# liliumFP1_application register map
Vendor: Nordic Semiconductor; Series: liliumFP1; File version: 1
CPU: CM33 r0p4, little endian, MPU, FPU, 3 interrupt priority bits, 480 interrupts
Registers are 32-bit, read-write, reset 0x0 unless marked. A register's access mark holds for its fields unless they carry their own. Offsets are from the block's base; [hi:lo] are bit positions; {n}, {i} and the like mark numbered series; 'fields as' and 'values as' point back to an identical list.

## BELLBOARD_NS — BELLBOARD APB registers 0
Base 0x4F09A000
Same registers: BELLBOARD_S 0x5F09A000
{0x0+4i} TASKS_TRIGGER[{i}] (i=0..31) wo — Description collection: Task TRIGGER[n]
  [0] TASKS_TRIGGER — Task TRIGGER[n]
    1=Trigger task
{0x100+4i} EVENTS_TRIGGERED[{i}] (i=0..31) — Description collection: Event TRIGGERED[n]
  [0] EVENTS_TRIGGERED — Event TRIGGERED[n]
    0=NotGenerated (Event not generated); 1=Generated (Event generated)
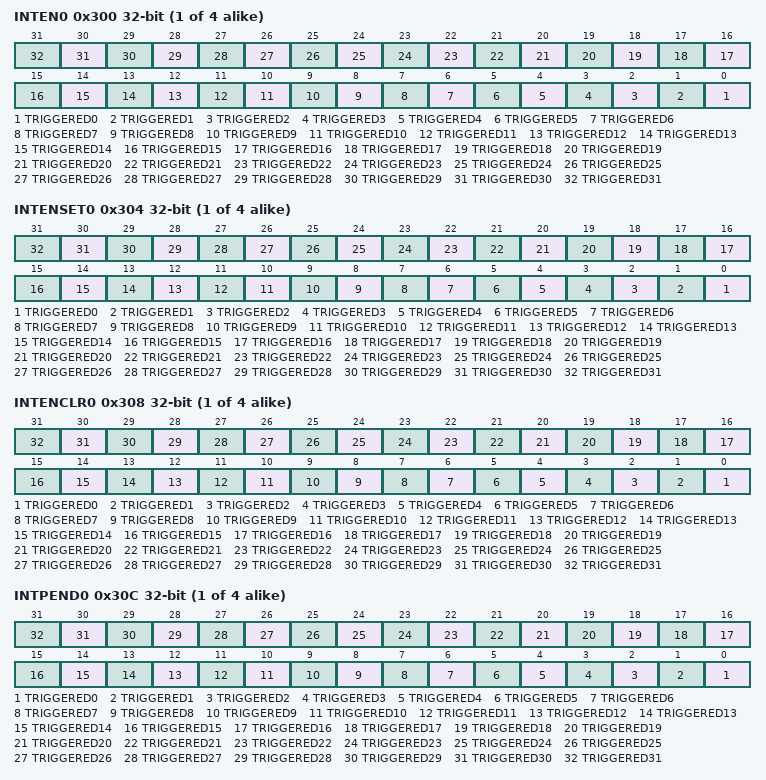
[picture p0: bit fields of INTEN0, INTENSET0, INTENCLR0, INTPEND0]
{0x300+0x10*i} INTEN{i} (i=0..3) — Enable or disable interrupt
  [all] fields
    0=Disabled; 1=Enabled
  [n] TRIGGERED{n} (n=0..31) — Enable or disable interrupt for event TRIGGERED[{n}]
{0x304+0x10*i} INTENSET{i} (i=0..3) — Enable interrupt
  [all] fields
    on read: 0=Disabled (Read: Disabled); 1=Enabled (Read: Enabled) | on write: 1=Set (Enable)
  [n] TRIGGERED{n} (n=0..31) — Write '1' to enable interrupt for event TRIGGERED[{n}]
{0x308+0x10*i} INTENCLR{i} (i=0..3) — Disable interrupt
  [all] fields
    on read: 0=Disabled (Read: Disabled); 1=Enabled (Read: Enabled) | on write: 1=Clear (Disable)
  [n] TRIGGERED{n} (n=0..31) — Write '1' to disable interrupt for event TRIGGERED[{n}]
{0x30C+0x10*i} INTPEND{i} ro (i=0..3) — Pending interrupts
  [all] fields
    on read: 0=NotPending (Read: Not pending); 1=Pending (Read: Pending)
  [n] TRIGGERED{n} (n=0..31) — Read pending status of interrupt for event TRIGGERED[{n}]

## GLOBAL_TDDCONF_NS — TDDCONF 0
Base 0xBF001000
Same registers: GLOBAL_TDDCONF_S 0xBF001000 (alternate view of GLOBAL_TDDCONF_NS)
0x400 SYSPWRUPREQ — System power-up request
  [0] ACTIVE — Activate power-up request
    0=NotActive (Power-up request not active); 1=Active (Power-up request active)
0x404 DBGPWRUPREQ — Debug power-up request
  fields as SYSPWRUPREQ
0x408 TRACEPORTSPEED — Trace port trace clock speed
  [1:0] SPEED — Trace clock speed
    0=Speed100MHz; 1=Speed50MHz; 2=Speed25MHz; 3=Speed12500KHz (Speed 12.5MHz)
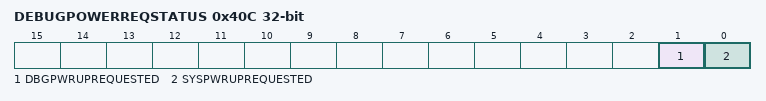
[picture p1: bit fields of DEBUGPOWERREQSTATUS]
0x40C DEBUGPOWERREQSTATUS ro — Combined effective system status of both SWJ-DP and TDDCONF registers originated power requests
  [1] DBGPWRUPREQUESTED — Debug domain powerup request status
    0=NoPowerReq (Power not requested); 1=Power requested
  [0] SYSPWRUPREQUESTED — System powerup request status
    0=NoPowerReq (Power not requested); 1=Power requested

## GLOBAL_TBM_NS — Trace buffer monitor 0
Base 0xBF003000
Same registers: GLOBAL_TBM_S 0xBF003000 (alternate view of GLOBAL_TBM_NS)
0x00 TASKS_START wo — Start counter
  [0] TASKS_START
    1=Trigger task
0x04 TASKS_STOP wo — Stop counter, clear counter value
  [0] TASKS_STOP
    1=Trigger task
0x08 TASKS_FLUSH wo — Stop counter, keep current counter value
  [0] TASKS_FLUSH
    1=Trigger task
0x100 EVENTS_HALFFULL — Counter value equals half-full
  [0] EVENTS_HALFFULL
    0=NotGenerated (Event not generated); 1=Generated (Event generated)
0x104 EVENTS_FULL — Counter value equals full
  [0] EVENTS_FULL
    values as EVENTS_HALFFULL.EVENTS_HALFFULL
0x108 EVENTS_FLUSH — Counter stopped due to flush
  [0] EVENTS_FLUSH
    values as EVENTS_HALFFULL.EVENTS_HALFFULL
0x200 SHORTS — Shortcuts between local events and tasks
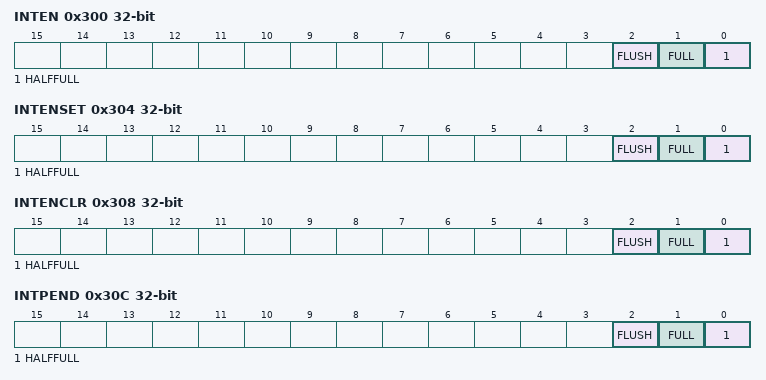
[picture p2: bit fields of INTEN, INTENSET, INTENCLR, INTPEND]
0x300 INTEN — Enable or disable interrupt
  [all] fields
    0=Disabled; 1=Enabled
  [2] FLUSH — Enable or disable interrupt for event FLUSH
  [1] FULL — Enable or disable interrupt for event FULL
  [0] HALFFULL — Enable or disable interrupt for event HALFFULL
0x304 INTENSET — Enable interrupt
  [all] fields
    on read: 0=Disabled (Read: Disabled); 1=Enabled (Read: Enabled) | on write: 1=Set (Enable)
  [2] FLUSH — Write '1' to enable interrupt for event FLUSH
  [1] FULL — Write '1' to enable interrupt for event FULL
  [0] HALFFULL — Write '1' to enable interrupt for event HALFFULL
0x308 INTENCLR — Disable interrupt
  [all] fields
    on read: 0=Disabled (Read: Disabled); 1=Enabled (Read: Enabled) | on write: 1=Clear (Disable)
  [2] FLUSH — Write '1' to disable interrupt for event FLUSH
  [1] FULL — Write '1' to disable interrupt for event FULL
  [0] HALFFULL — Write '1' to disable interrupt for event HALFFULL
0x30C INTPEND ro — Pending interrupts
  [all] fields
    on read: 0=NotPending (Read: Not pending); 1=Pending (Read: Pending)
  [2] FLUSH — Read pending status of interrupt for event FLUSH
  [1] FULL — Read pending status of interrupt for event FULL
  [0] HALFFULL — Read pending status of interrupt for event HALFFULL
0x400 BUFFERSIZE reset 0x1FF — System RAM trace buffer total size in bytes
  [11:0] BUFFERSIZE — Must only be configured in STOP mode. Must be multiple of 16 bytes to make half-buffer size always 64 bit word aligned. BUFFERSIZE LSB byte always fixed as 0xF to 16 bytes boundary. Minimum BUFFERSIZE value 0x00F i.e. 16 bytes, maximum value 0xFFF i.e. 4096 bytes.
    15=Min (16 bytes); 0xFFF=Max (4096 bytes)
0x404 COUNT ro — Counter current value
  [11:0] COUNT
